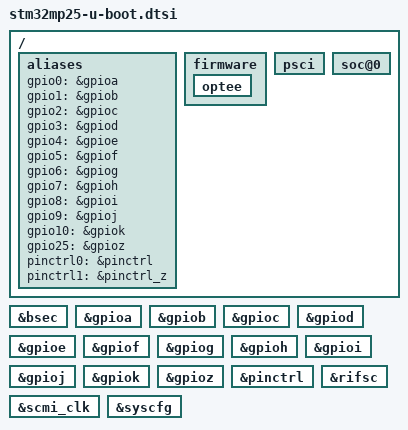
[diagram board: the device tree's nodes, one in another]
// SPDX-License-Identifier: GPL-2.0-or-later OR BSD-3-Clause
/*
 * Copyright : STMicroelectronics 2023
 */

/ {
	aliases {
		gpio0 = &gpioa;
		gpio1 = &gpiob;
		gpio2 = &gpioc;
		gpio3 = &gpiod;
		gpio4 = &gpioe;
		gpio5 = &gpiof;
		gpio6 = &gpiog;
		gpio7 = &gpioh;
		gpio8 = &gpioi;
		gpio9 = &gpioj;
		gpio10 = &gpiok;
		gpio25 = &gpioz;
		pinctrl0 = &pinctrl;
		pinctrl1 = &pinctrl_z;
	};

	firmware {
		optee {
			bootph-all;
		};
	};

	/* need PSCI for sysreset during board_f */
	psci {
		bootph-all;
	};

	soc@0 {
		bootph-all;
	};
};

&bsec {
	bootph-all;
};

&gpioa {
	bootph-all;
};

&gpiob {
	bootph-all;
};

&gpioc {
	bootph-all;
};

&gpiod {
	bootph-all;
};

&gpioe {
	bootph-all;
};

&gpiof {
	bootph-all;
};

&gpiog {
	bootph-all;
};

&gpioh {
	bootph-all;
};

&gpioi {
	bootph-all;
};

&gpioj {
	bootph-all;
};

&gpiok {
	bootph-all;
};

&gpioz {
	bootph-all;
};

&pinctrl {
	bootph-all;
};

&rifsc {
	bootph-all;
};

&scmi_clk {
	bootph-all;
};

&syscfg {
	bootph-all;
};
